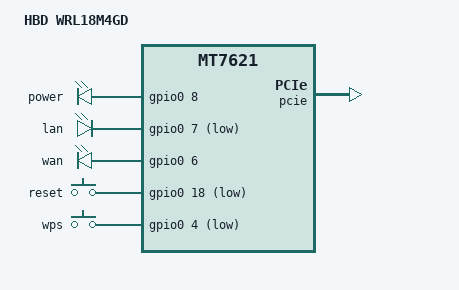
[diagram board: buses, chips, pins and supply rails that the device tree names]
/dts-v1/;

#include "mt7621.dtsi"
#include <dt-bindings/input/input.h>
#include "mt7621-raeth-gmac2.dtsi"
#include "mt7621-pinctrl-default-gpio.dtsi"
#include "mt7621-nand-128m-layout.dtsi"

/ {
	compatible = "mediatek,mt7621-soc";
	model = "HBD WRL18M4GD";

	chosen {
		bootargs = "console=ttyS0,115200";
	};

	leds {
		compatible = "gpio-leds";

		stat_red {
			label = "power";
			gpios = <&gpio0 8 GPIO_ACTIVE_HIGH>;
		};

		stat_green {
			label = "lan";
			gpios = <&gpio0 7 GPIO_ACTIVE_LOW>;
		};

		stat_blue {
			label = "wan";
			gpios = <&gpio0 6 GPIO_ACTIVE_HIGH>;
		};
	};

	gpio-keys-polled {
		compatible = "gpio-keys-polled";
		#address-cells = <1>;
		#size-cells = <0>;
		poll-interval = <20>;

		reset {
			label = "reset";
			gpios = <&gpio0 18 GPIO_ACTIVE_LOW>;
			linux,code = <KEY_RESTART>;
		};

		wps {
			label = "wps";
			gpios = <&gpio0 4 GPIO_ACTIVE_LOW>;
			linux,code = <KEY_WPS_BUTTON>;
		};
	};
};

&pcie {
	status = "okay";
};
